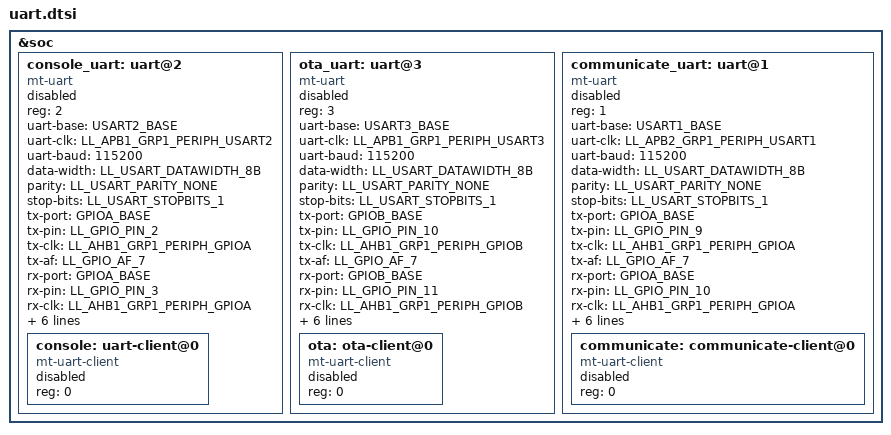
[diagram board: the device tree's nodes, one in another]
// SPDX-License-Identifier: Apache-2.0
/*
 * STM32F407 UART 板级片段 — USART2 (PA2=TX, PA3=RX, AF7) console 日志口
 *
 * 用法: board/dts/board.dts 中 #include "uart.dtsi"
 * label=console (client) 供 hal/system/syscalls.c _write 按 label 查找输出日志
 *
 * 数值宏直投 LL_InitTypeDef (DataWidth/StopBits/Parity 等由 hal_uart_stm32.c
 * 零翻译透传), 必须使用 LL 库宏而非裸数字。
 *
 * 厂商宏经 VENDOR_INC_DIRS / dtc-lite -I 解析（见根 CMakeLists.txt）
 */
#include <stm32f4xx_ll_gpio.h>
#include <stm32f4xx_ll_usart.h>
#include <stm32f4xx_ll_bus.h>
#include <stm32f4xx_ll_dma.h>

&soc {
	console_uart: uart@2 {
		compatible = "mt-uart";
		reg = <2>;
		#address-cells = <1>;
		#size-cells = <0>;
		uart-base  = <USART2_BASE>;
		uart-clk   = <LL_APB1_GRP1_PERIPH_USART2>;
		uart-baud  = <115200>;
		data-width = <LL_USART_DATAWIDTH_8B>;
		parity     = <LL_USART_PARITY_NONE>;
		stop-bits  = <LL_USART_STOPBITS_1>;
		tx-port = <GPIOA_BASE>;
		tx-pin  = <LL_GPIO_PIN_2>;
		tx-clk  = <LL_AHB1_GRP1_PERIPH_GPIOA>;
		tx-af   = <LL_GPIO_AF_7>;
		rx-port = <GPIOA_BASE>;
		rx-pin  = <LL_GPIO_PIN_3>;
		rx-clk  = <LL_AHB1_GRP1_PERIPH_GPIOA>;
		rx-af   = <LL_GPIO_AF_7>;
		/* 接收必须走中断: 本芯片 UART 无硬件 FIFO, 纯轮询读会在两次轮询之间
		 * 被硬件覆盖而丢字节。irqn 用数字 (dtc-lite 不展开 CMSIS 枚举):
		 * USART1=37 / USART2=38 / USART3=39 */
		irqn = <38>;          /* USART2_IRQn */
		irq-priority = <5>;
		it-enable = <1>;
		/* TX DMA: 短元组 <handle stream channel priority memory_size enable>
		 * USART2_TX 的固定映射是 DMA1 Stream6 Channel4 (见 RM0090 DMA 请求映射表)。
		 * 配了它 hal_uart_write 就自动走 DMA (len<=512), 不必上层区分 API。
		 * @warning 通道填错不会报错, 只会静默不搬数据 (口上没输出) —— 换口务必查表。 */
		dma-cfg = <DMA1_BASE LL_DMA_STREAM_6 LL_DMA_CHANNEL_4
		           LL_DMA_PRIORITY_MEDIUM LL_DMA_MDATAALIGN_BYTE 1>;
		status = "disabled";

		console: uart-client@0 {
			compatible = "mt-uart-client";
			reg = <0>;
			status = "disabled";
		};
	};

	/* OTA 固件流口: USART3 (PB10=TX, PB11=RX, AF7) — 与 console(USART2) 分流,
	 * 避免日志字节混进固件流。业务按 label=ota (client) 查找。 */
	ota_uart: uart@3 {
		compatible = "mt-uart";
		reg = <3>;
		#address-cells = <1>;
		#size-cells = <0>;
		uart-base  = <USART3_BASE>;
		uart-clk   = <LL_APB1_GRP1_PERIPH_USART3>;
		uart-baud  = <115200>;
		data-width = <LL_USART_DATAWIDTH_8B>;
		parity     = <LL_USART_PARITY_NONE>;
		stop-bits  = <LL_USART_STOPBITS_1>;
		tx-port = <GPIOB_BASE>;
		tx-pin  = <LL_GPIO_PIN_10>;
		tx-clk  = <LL_AHB1_GRP1_PERIPH_GPIOB>;
		tx-af   = <LL_GPIO_AF_7>;
		rx-port = <GPIOB_BASE>;
		rx-pin  = <LL_GPIO_PIN_11>;
		rx-clk  = <LL_AHB1_GRP1_PERIPH_GPIOB>;
		rx-af   = <LL_GPIO_AF_7>;
		/* OTA 固件流口: 中断接收 (irqn=39 即 USART3_IRQn), 否则大流量必丢 */
		irqn = <39>;          /* USART3_IRQn */
		irq-priority = <5>;
		it-enable = <1>;
		/* TX DMA: USART3_TX 固定映射 DMA1 Stream3 Channel4 (RM0090)。
		 * 注意 DTS 里 SPI2 未配 DMA, 故 Stream3 无冲突; 若日后给 SPI2 开 DMA
		 * (SPI2_TX 也是 DMA1 Stream3) 必须先把本口换到别的空闲流。 */
		dma-cfg = <DMA1_BASE LL_DMA_STREAM_3 LL_DMA_CHANNEL_4
		           LL_DMA_PRIORITY_MEDIUM LL_DMA_MDATAALIGN_BYTE 1>;
		status = "disabled";

		/* 业务侧必须拿 client 设备: 只有 mt-uart-client 注册 fops,
		 * open 时才会经 uart_vfs_open -> uart_bus_open 打开硬件 (使能 CR1.RE) */
		ota: ota-client@0 {
			compatible = "mt-uart-client";
			reg = <0>;
			status = "disabled";
		};
	};

	/* 业务通信口: USART1 (PA9=TX, PA10=RX, AF7) — 业务按 label=communicate (client) 查找
	 * 独立于 console(USART2)/OTA(USART3), 三者互不抢字节。
	 * 注意 USART1/USART6 挂在 APB2, 时钟掩码必须用 LL_APB2_GRP1_PERIPH_*。 */
	communicate_uart: uart@1 {
		compatible = "mt-uart";
		reg = <1>;
		#address-cells = <1>;
		#size-cells = <0>;
		uart-base  = <USART1_BASE>;
		uart-clk   = <LL_APB2_GRP1_PERIPH_USART1>;
		uart-baud  = <115200>;
		data-width = <LL_USART_DATAWIDTH_8B>;
		parity     = <LL_USART_PARITY_NONE>;
		stop-bits  = <LL_USART_STOPBITS_1>;
		tx-port = <GPIOA_BASE>;
		tx-pin  = <LL_GPIO_PIN_9>;
		tx-clk  = <LL_AHB1_GRP1_PERIPH_GPIOA>;
		tx-af   = <LL_GPIO_AF_7>;
		rx-port = <GPIOA_BASE>;
		rx-pin  = <LL_GPIO_PIN_10>;
		rx-clk  = <LL_AHB1_GRP1_PERIPH_GPIOA>;
		rx-af   = <LL_GPIO_AF_7>;
		/* 业务命令口: 中断接收 (irqn=37 即 USART1_IRQn), 否则整条命令行会被丢 */
		irqn = <37>;          /* USART1_IRQn */
		irq-priority = <5>;
		it-enable = <1>;
		/* TX DMA: USART1_TX 固定映射 DMA2 Stream7 Channel4 (RM0090) */
		dma-cfg = <DMA2_BASE LL_DMA_STREAM_7 LL_DMA_CHANNEL_4
		           LL_DMA_PRIORITY_MEDIUM LL_DMA_MDATAALIGN_BYTE 1>;
		status = "disabled";

		/* 业务侧必须拿 client 设备: 只有 mt-uart-client 注册 fops,
		 * open 时才会经 uart_vfs_open -> uart_bus_open 打开硬件 (使能 CR1.RE) */
		communicate: communicate-client@0 {
			compatible = "mt-uart-client";
			reg = <0>;
			status = "disabled";
		};
	};
};
